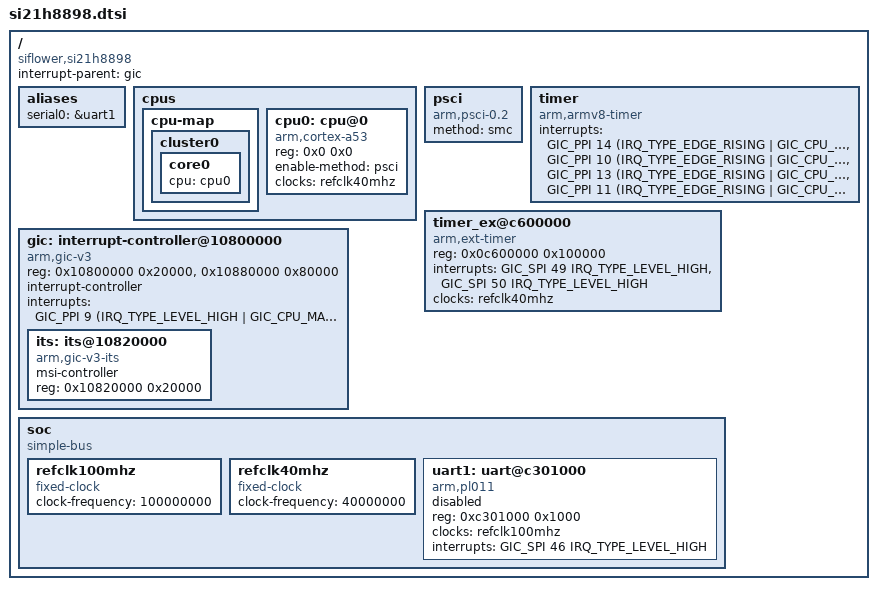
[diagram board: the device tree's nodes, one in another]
/*
 * Copyright 2016 SiFlower Corporation.
 * Copyright 2016 Linaro Ltd.
 *
 * This file is dual-licensed: you can use it either under the terms
 * of the GPL or the X11 license, at your option. Note that this dual
 * licensing only applies to this file, and not this project as a
 * whole.
 *
 *  a) This library is free software; you can redistribute it and/or
 *     modify it under the terms of the GNU General Public License as
 *     published by the Free Software Foundation; either version 2 of the
 *     License, or (at your option) any later version.
 *
 *     This library is distributed in the hope that it will be useful,
 *     but WITHOUT ANY WARRANTY; without even the implied warranty of
 *     MERCHANTABILITY or FITNESS FOR A PARTICULAR PURPOSE.  See the
 *     GNU General Public License for more details.
 *
 * Or, alternatively,
 *
 *  b) Permission is hereby granted, free of charge, to any person
 *     obtaining a copy of this software and associated documentation
 *     files (the "Software"), to deal in the Software without
 *     restriction, including without limitation the rights to use,
 *     copy, modify, merge, publish, distribute, sublicense, and/or
 *     sell copies of the Software, and to permit persons to whom the
 *     Software is furnished to do so, subject to the following
 *     conditions:
 *
 *     The above copyright notice and this permission notice shall be
 *     included in all copies or substantial portions of the Software.
 *
 *     THE SOFTWARE IS PROVIDED "AS IS", WITHOUT WARRANTY OF ANY KIND,
 *     EXPRESS OR IMPLIED, INCLUDING BUT NOT LIMITED TO THE WARRANTIES
 *     OF MERCHANTABILITY, FITNESS FOR A PARTICULAR PURPOSE AND
 *     NONINFRINGEMENT. IN NO EVENT SHALL THE AUTHORS OR COPYRIGHT
 *     HOLDERS BE LIABLE FOR ANY CLAIM, DAMAGES OR OTHER LIABILITY,
 *     WHETHER IN AN ACTION OF CONTRACT, TORT OR OTHERWISE, ARISING
 *     FROM, OUT OF OR IN CONNECTION WITH THE SOFTWARE OR THE USE OR
 *     OTHER DEALINGS IN THE SOFTWARE.
 */

#include <dt-bindings/input/input.h>
#include <dt-bindings/interrupt-controller/arm-gic.h>
#include <dt-bindings/gpio/gpio.h>
// #include <dt-bindings/clock/si21h8898-clock.h>


/ {
	compatible = "siflower,si21h8898";
	#address-cells = <1>;
	#size-cells = <1>;
	interrupt-parent = <&gic>;

	aliases {
		serial0 = &uart1;
	};

	cpus {
		#address-cells = <2>;
		#size-cells = <0>;

		cpu-map {
			cluster0 {
				core0 {
					cpu = <&cpu0>;
				};
			};
		};

		cpu0: cpu@0 {
			device_type = "cpu";
			compatible = "arm,cortex-a53";
			reg = <0x0 0x0>;
			enable-method = "psci";
			clocks = <&refclk40mhz>;
		};
	};

	psci {
		compatible = "arm,psci-0.2";
		method = "smc";
	};

	timer {
		compatible = "arm,armv8-timer";
		interrupts = <GIC_PPI 14 (IRQ_TYPE_EDGE_RISING | GIC_CPU_MASK_SIMPLE(4))>,
					 <GIC_PPI 10 (IRQ_TYPE_EDGE_RISING | GIC_CPU_MASK_SIMPLE(4))>,
					 <GIC_PPI 13 (IRQ_TYPE_EDGE_RISING | GIC_CPU_MASK_SIMPLE(4))>,
					 <GIC_PPI 11 (IRQ_TYPE_EDGE_RISING | GIC_CPU_MASK_SIMPLE(4))>;
	};

	timer_ex@c600000 {
			compatible = "arm,ext-timer";
			reg = <0x0c600000 0x100000>;	/* 1MB */
			interrupts = <GIC_SPI 49 IRQ_TYPE_LEVEL_HIGH>,
						<GIC_SPI 50 IRQ_TYPE_LEVEL_HIGH>;
			clocks = <&refclk40mhz>;
	};

	gic: interrupt-controller@10800000 {
		compatible = "arm,gic-v3";
		#interrupt-cells = <3>;
		#address-cells = <1>;
		#size-cells = <1>;
		ranges;
		reg = <0x10800000 0x20000>,	// GICD
			<0x10880000 0x80000>;	// GICR * 8
		interrupt-controller;
		interrupts = <GIC_PPI 9 (IRQ_TYPE_LEVEL_HIGH | GIC_CPU_MASK_SIMPLE(4))>;

		its: its@10820000 {
			compatible = "arm,gic-v3-its";
			msi-controller;
			#msi-cells = <1>;
			reg = <0x10820000 0x20000>;
		};
	};

	soc {
		#address-cells = <1>;
		#size-cells = <1>;
		compatible = "simple-bus";
		ranges;

		refclk100mhz: refclk100mhz {
			compatible = "fixed-clock";
			#clock-cells = <0>;
			clock-frequency = <100000000>;
		};

		refclk40mhz: refclk40mhz {
			compatible = "fixed-clock";
			#clock-cells = <0>;
			clock-frequency = <40000000>;
		};

		uart1: uart@c301000 {
			compatible = "arm,pl011", "arm,primecell";
			reg = <0xc301000 0x1000>;
			clocks = <&refclk100mhz>;
			clock-names = "apb_pclk";
			interrupts = <GIC_SPI 46 IRQ_TYPE_LEVEL_HIGH>;
			status = "disabled";
		};
	};
};
